# STM32F107 register map
File version: 1.1
CPU: CM3 r1p1, little endian, no MPU, no FPU, 4 interrupt priority bits
Registers are 32-bit, read-write, reset 0x0 unless marked. A register's access mark holds for its fields unless they carry their own. Offsets are from the block's base; [hi:lo] are bit positions; {n}, {i} and the like mark numbered series; <NAME> marks a mode.

## DBGMCU — Debug support
Base 0xE0042000
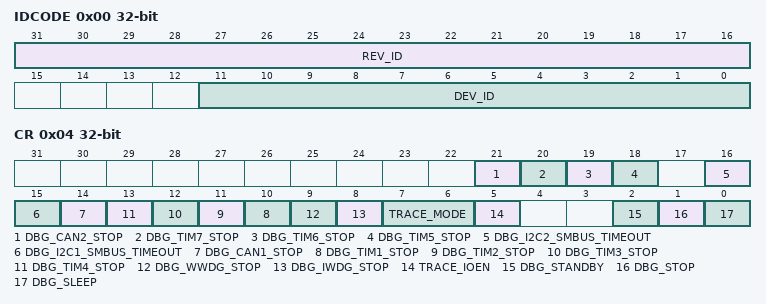
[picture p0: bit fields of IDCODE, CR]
0x00 IDCODE ro — DBGMCU_IDCODE
  [31:16] REV_ID, [11:0] DEV_ID
0x04 CR — DBGMCU_CR
  [21] DBG_CAN2_STOP, [20] DBG_TIM7_STOP, [19] DBG_TIM6_STOP, [18] DBG_TIM5_STOP, [16] DBG_I2C2_SMBUS_TIMEOUT, [15] DBG_I2C1_SMBUS_TIMEOUT, [14] DBG_CAN1_STOP, [n+9] DBG_TIM{n}_STOP (n=1..4), [9] DBG_WWDG_STOP, [8] DBG_IWDG_STOP, [7:6] TRACE_MODE, [5] TRACE_IOEN, [2] DBG_STANDBY, [1] DBG_STOP, [0] DBG_SLEEP

## CRC — CRC calculation unit
Base 0x40023000
0x00 DR reset 0xFFFFFFFF — Data register
  [31:0] DR — Data Register
0x04 IDR — Independent Data register
  [7:0] IDR
0x08 CR wo — Control register
  [0] RESET — Reset bit
    1=Resets the CRC calculation unit and sets the data register to 0xFFFF FFFF

## FLASH
Base 0x40022000
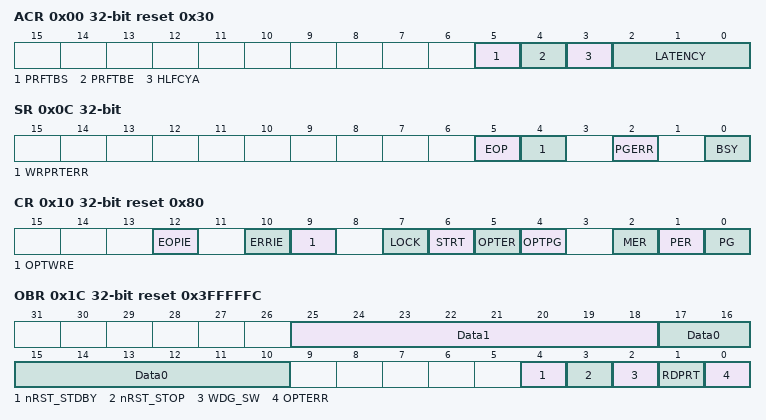
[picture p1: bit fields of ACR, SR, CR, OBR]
0x00 ACR access per field reset 0x30 — Flash access control register
  [5] PRFTBS ro — Prefetch buffer status
  [4] PRFTBE rw — Prefetch buffer enable
  [3] HLFCYA rw — Flash half cycle access enable
  [2:0] LATENCY rw
    0=WS0 (Zero wait state, if 0 < SYSCLK≤ 24 MHz); 1=WS1 (One wait state, if 24 MHz < SYSCLK ≤ 48 MHz); 2=WS2 (Two wait states, if 48 MHz < SYSCLK ≤ 72 MHz)
0x04 KEYR wo — Flash key register
  [31:0] KEY — FPEC key
0x08 OPTKEYR wo — Flash option key register
  [31:0] OPTKEY — Option byte key
0x0C SR access per field — Status register
  [5] EOP rw — End of operation
  [4] WRPRTERR rw — Write protection error
  [2] PGERR rw — Programming error
  [0] BSY ro — Busy
0x10 CR reset 0x80 — Control register
  [12] EOPIE — End of operation interrupt enable
  [10] ERRIE — Error interrupt enable
  [9] OPTWRE — Option bytes write enable
  [7] LOCK
  [6] STRT — Start
  [5] OPTER — Option byte erase
  [4] OPTPG — Option byte programming
  [2] MER — Mass Erase
  [1] PER — Page Erase
  [0] PG — Programming
0x14 AR wo — Flash address register
  [31:0] FAR — Flash Address
0x1C OBR ro reset 0x3FFFFFC — Option byte register
  [25:18] Data1
  [17:10] Data0
  [4] nRST_STDBY
  [3] nRST_STOP
  [2] WDG_SW
  [1] RDPRT — Read protection
  [0] OPTERR — Option byte error
0x20 WRPR ro reset 0xFFFFFFFF — Write protection register
  [31:0] WRP — Write protect

## NVIC — Nested Vectored Interrupt Controller
Base 0xE000E100
0x00 ISER0 — Interrupt Set-Enable Register
  [31:0] SETENA
0x04 ISER1 — Interrupt Set-Enable Register
  [31:0] SETENA
0x80 ICER0 — Interrupt Clear-Enable Register
  [31:0] CLRENA
0x84 ICER1 — Interrupt Clear-Enable Register
  [31:0] CLRENA
0x100 ISPR0 — Interrupt Set-Pending Register
  [31:0] SETPEND
0x104 ISPR1 — Interrupt Set-Pending Register
  [31:0] SETPEND
0x180 ICPR0 — Interrupt Clear-Pending Register
  [31:0] CLRPEND
0x184 ICPR1 — Interrupt Clear-Pending Register
  [31:0] CLRPEND
0x200 IABR0 ro — Interrupt Active Bit Register
  [31:0] ACTIVE
0x204 IABR1 ro — Interrupt Active Bit Register
  [31:0] ACTIVE
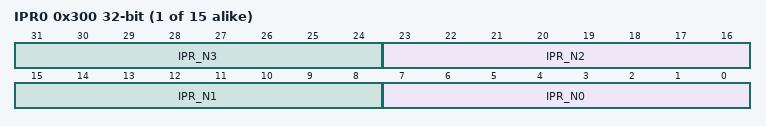
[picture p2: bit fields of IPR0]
{0x300+4i} IPR{i} (i=0..14) — Interrupt Priority Register
  [8n+7:8n] IPR_N{n} (n=0..3)

## MPU — Memory protection unit
Base 0xE000ED90
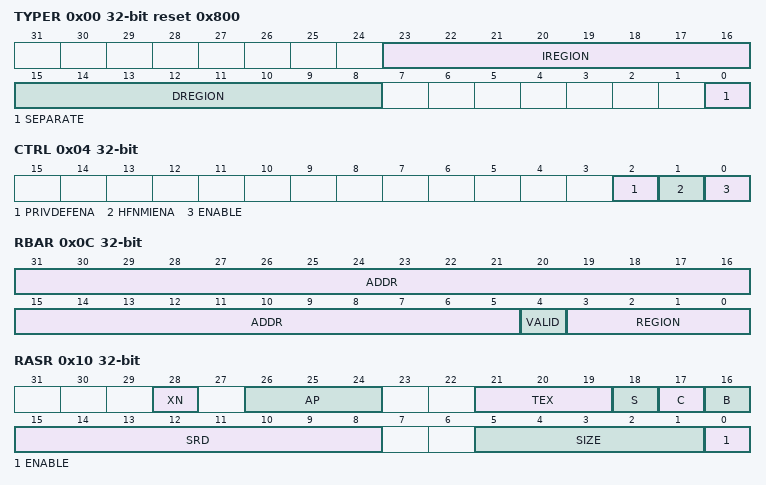
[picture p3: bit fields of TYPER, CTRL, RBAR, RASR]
0x00 TYPER ro reset 0x800 — MPU type register
  [23:16] IREGION — Number of MPU instruction regions
  [15:8] DREGION — Number of MPU data regions
  [0] SEPARATE — Separate flag
0x04 CTRL ro — MPU control register
  [2] PRIVDEFENA — Enable priviliged software access to default memory map
  [1] HFNMIENA — Enables the operation of MPU during hard fault
  [0] ENABLE — Enables the MPU
0x08 RNR — MPU region number register
  [7:0] REGION — MPU region
0x0C RBAR — MPU region base address register
  [31:5] ADDR — Region base address field
  [4] VALID — MPU region number valid
  [3:0] REGION — MPU region field
0x10 RASR — MPU region attribute and size register
  [28] XN — Instruction access disable bit
  [26:24] AP — Access permission
  [21:19] TEX — memory attribute
  [18] S — Shareable memory attribute
  [17] C — memory attribute
  [16] B — memory attribute
  [15:8] SRD — Subregion disable bits
  [5:1] SIZE — Size of the MPU protection region
  [0] ENABLE — Region enable bit.

## SCB_ACTRL — System control block ACTLR
Base 0xE000E008
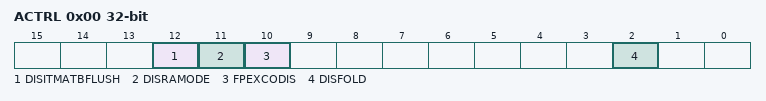
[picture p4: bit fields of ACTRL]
0x00 ACTRL — Auxiliary control register
  [12] DISITMATBFLUSH, [11] DISRAMODE, [10] FPEXCODIS, [2] DISFOLD

## NVIC_STIR — Nested vectored interrupt controller
Base 0xE000EF00
0x00 STIR — Software trigger interrupt register
  [8:0] INTID — Software generated interrupt ID

## STK — SysTick timer
Base 0xE000E010
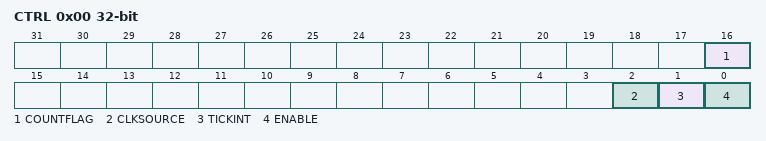
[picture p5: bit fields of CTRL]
0x00 CTRL — SysTick control and status register
  [16] COUNTFLAG
  [2] CLKSOURCE — Clock source selection
  [1] TICKINT — SysTick exception request enable
  [0] ENABLE — Counter enable
0x04 LOAD_ — SysTick reload value register
  [23:0] RELOAD — RELOAD value
0x08 VAL — SysTick current value register
  [23:0] CURRENT — Current counter value
0x0C CALIB — SysTick calibration value register
  [23:0] TENMS — Calibration value
